# STM32U595 register map
File version: 1.7
CPU: CM33 r0p1, little endian, MPU, FPU, 4 interrupt priority bits
Registers are 32-bit, read-write, reset 0x0 unless marked. A register's access mark holds for its fields unless they carry their own. Offsets are from the block's base; [hi:lo] are bit positions; {n}, {i} and the like mark numbered series.

## GTZC1_MPCBB1
Base 0x40032C00
Same registers: SEC_GTZC1_MPCBB1 0x50032C00
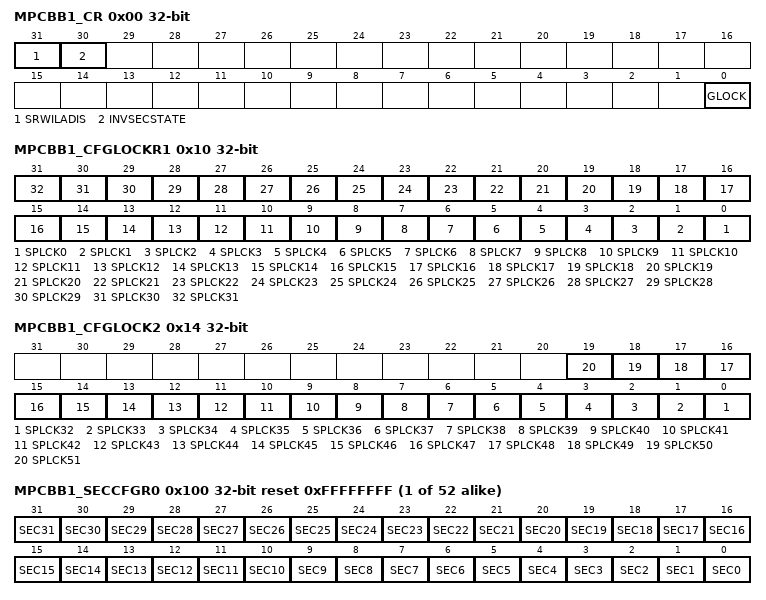
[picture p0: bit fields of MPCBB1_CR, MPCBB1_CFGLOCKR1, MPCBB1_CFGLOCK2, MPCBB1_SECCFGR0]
0x00 MPCBB1_CR — MPCBB control register
  [31] SRWILADIS — secure read/write illegal access disable
  [30] INVSECSTATE — SRAMx clocks security state
  [0] GLOCK — lock the control register of the MPCBB until next reset
0x10 MPCBB1_CFGLOCKR1 — GTZC1 SRAMz MPCBB configuration lock register 1
  [n] SPLCK{n} (n=0..31)
0x14 MPCBB1_CFGLOCK2 — GTZC1 SRAMz MPCBB configuration lock register 2
  [n-32] SPLCK{n} (n=32..51)
{0x100+4i} MPCBB1_SECCFGR{i} reset 0xFFFFFFFF (i=0..51) — MPCBBx security configuration for super-block x register
  [n] SEC{n} (n=0..31)
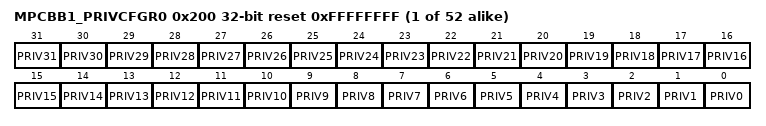
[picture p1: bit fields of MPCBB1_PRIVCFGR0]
{0x200+4i} MPCBB1_PRIVCFGR{i} reset 0xFFFFFFFF (i=0..51) — MPCBB privileged configuration for super-block x register
  [n] PRIV{n} (n=0..31)

## GTZC1_MPCBB2
Base 0x40033000
Same registers: SEC_GTZC1_MPCBB2 0x50033000
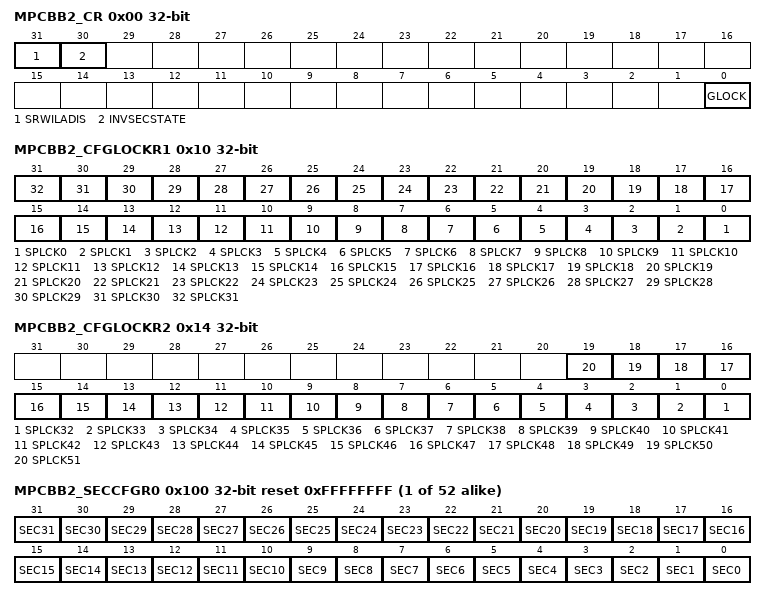
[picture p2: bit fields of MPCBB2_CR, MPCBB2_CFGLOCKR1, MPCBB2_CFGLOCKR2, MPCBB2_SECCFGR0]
0x00 MPCBB2_CR — MPCBB control register
  [31] SRWILADIS — secure read/write illegal access disable
  [30] INVSECSTATE — SRAMx clocks security state
  [0] GLOCK — lock the control register of the MPCBB until next reset
0x10 MPCBB2_CFGLOCKR1 — GTZC1 SRAMz MPCBB configuration lock register
  [n] SPLCK{n} (n=0..31)
0x14 MPCBB2_CFGLOCKR2 — GTZC1 SRAMz MPCBB configuration lock register 2
  [n-32] SPLCK{n} (n=32..51)
{0x100+4i} MPCBB2_SECCFGR{i} reset 0xFFFFFFFF (i=0..51) — MPCBBx security configuration for super-block x register
  [n] SEC{n} (n=0..31)
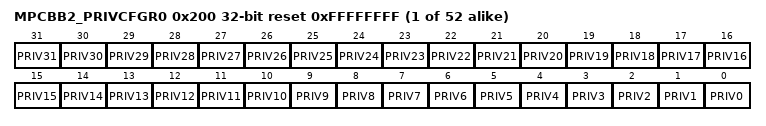
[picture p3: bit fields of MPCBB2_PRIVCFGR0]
{0x200+4i} MPCBB2_PRIVCFGR{i} reset 0xFFFFFFFF (i=0..51) — MPCBB privileged configuration for super-block x register
  [n] PRIV{n} (n=0..31)

## GTZC1_MPCBB3
Base 0x40033400
Same registers: SEC_GTZC1_MPCBB3 0x50033400
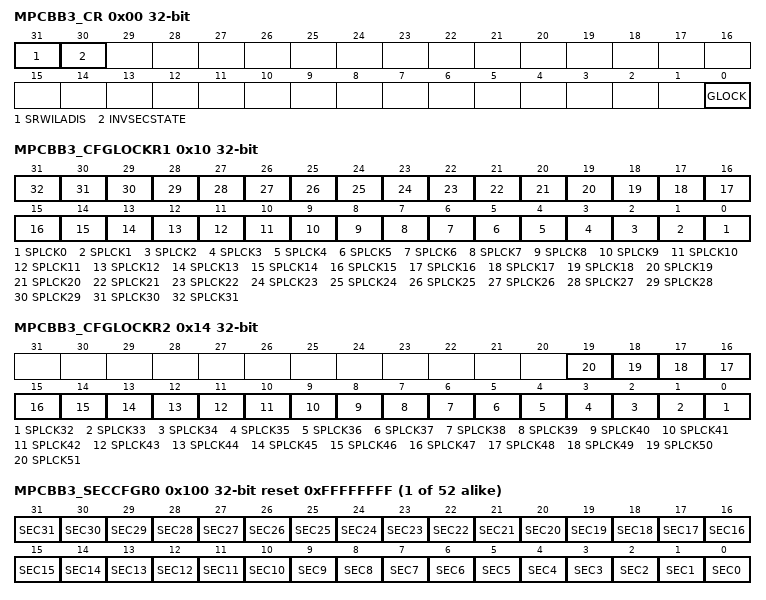
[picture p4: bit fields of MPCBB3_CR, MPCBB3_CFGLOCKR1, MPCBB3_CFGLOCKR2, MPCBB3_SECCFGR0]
0x00 MPCBB3_CR — MPCBB control register
  [31] SRWILADIS — secure read/write illegal access disable
  [30] INVSECSTATE — SRAMx clocks security state
  [0] GLOCK — lock the control register of the MPCBB until next reset
0x10 MPCBB3_CFGLOCKR1 — GTZC1 SRAMz MPCBB configuration lock register
  [n] SPLCK{n} (n=0..31)
0x14 MPCBB3_CFGLOCKR2 — GTZC1 SRAMz MPCBB configuration lock register 2
  [n-32] SPLCK{n} (n=32..51)
{0x100+4i} MPCBB3_SECCFGR{i} reset 0xFFFFFFFF (i=0..51) — MPCBBx security configuration for super-block x register
  [n] SEC{n} (n=0..31)
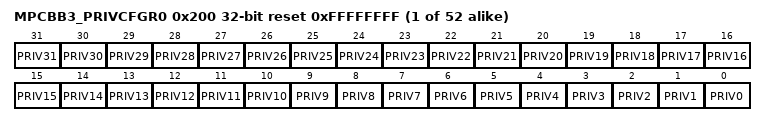
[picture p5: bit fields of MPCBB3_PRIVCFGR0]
{0x200+4i} MPCBB3_PRIVCFGR{i} reset 0xFFFFFFFF (i=0..51) — MPCBB privileged configuration for super-block x register
  [n] PRIV{n} (n=0..31)

## GTZC1_MPCBB5
Base 0x40033800
Same registers: SEC_GTZC1_MPCBB5 0x50033800
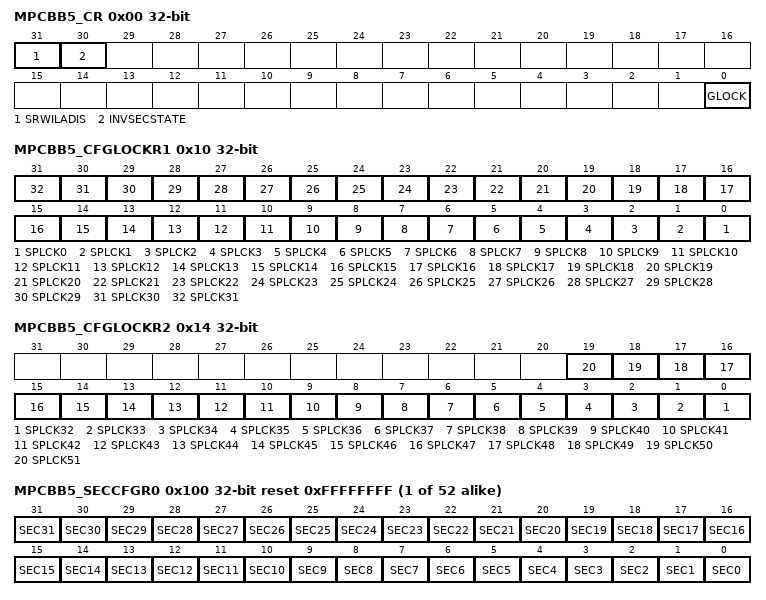
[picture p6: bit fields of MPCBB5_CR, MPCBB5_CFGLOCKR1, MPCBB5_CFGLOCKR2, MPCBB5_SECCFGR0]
0x00 MPCBB5_CR — MPCBB control register
  [31] SRWILADIS — secure read/write illegal access disable
  [30] INVSECSTATE — SRAMx clocks security state
  [0] GLOCK — lock the control register of the MPCBB until next reset
0x10 MPCBB5_CFGLOCKR1 — GTZC1 SRAMz MPCBB configuration lock register
  [n] SPLCK{n} (n=0..31)
0x14 MPCBB5_CFGLOCKR2 — GTZC1 SRAMz MPCBB configuration lock register 2
  [n-32] SPLCK{n} (n=32..51)
{0x100+4i} MPCBB5_SECCFGR{i} reset 0xFFFFFFFF (i=0..51) — MPCBBx security configuration for super-block x register
  [n] SEC{n} (n=0..31)
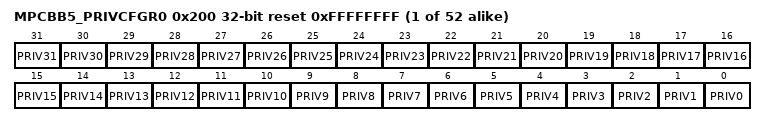
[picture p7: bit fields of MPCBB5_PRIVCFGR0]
{0x200+4i} MPCBB5_PRIVCFGR{i} reset 0xFFFFFFFF (i=0..51) — MPCBB privileged configuration for super-block x register
  [n] PRIV{n} (n=0..31)

## GTZC2_MPCBB4
Base 0x46023800
Same registers: SEC_GTZC2_MPCBB4 0x56023800
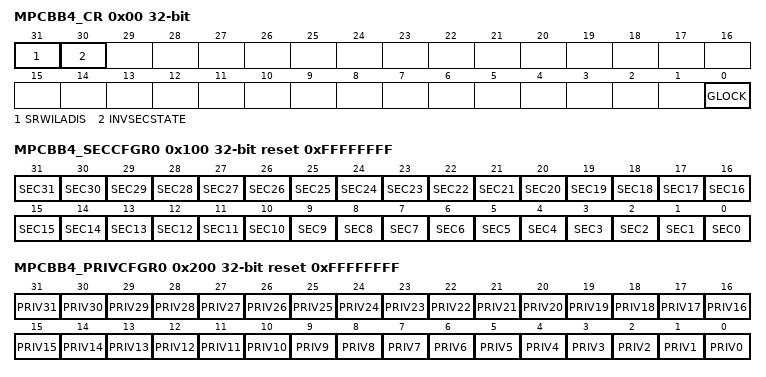
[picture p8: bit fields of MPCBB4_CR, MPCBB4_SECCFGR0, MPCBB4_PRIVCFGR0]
0x00 MPCBB4_CR — MPCBB control register
  [31] SRWILADIS — secure read/write illegal access disable
  [30] INVSECSTATE — SRAMx clocks security state
  [0] GLOCK — lock the control register of the MPCBB until next reset
0x10 MPCBB4_CFGLOCK — GTZC2 SRAM4 MPCBB configuration lock register
  [0] SPLCK0 — Security/privilege configuration lock for super-block 0
0x100 MPCBB4_SECCFGR0 reset 0xFFFFFFFF — MPCBB security configuration for super-block 0 register
  [n] SEC{n} (n=0..31)
0x200 MPCBB4_PRIVCFGR0 reset 0xFFFFFFFF — MPCBB privileged configuration for super-block 0 register
  [n] PRIV{n} (n=0..31)

## Notices in the file
Copyright (c) 2025 STMicroelectronics.
SPDX-License-Identifier: Apache-2.0
Licensed under the Apache License, Version 2.0 (the "License");
you may not use this file except in compliance with the License.
You may obtain a copy of the License at
http://www.apache.org/licenses/LICENSE-2.0
Unless required by applicable law or agreed to in writing, software
distributed under the License is distributed on an "AS IS" BASIS,
WITHOUT WARRANTIES OR CONDITIONS OF ANY KIND, either express or implied.
See the License for the specific language governing permissions and
limitations under the License.
